AUTOSAR XML (schema 4.0)
standard types defined: uint8, uint16
package /System
  system ExampleSystem
    system mapping SystemMapping
      ecu mapping ECU0_Mapping: ecu=ECU0
  ecu instance ECU0: controller=Controller0
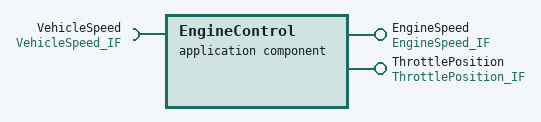
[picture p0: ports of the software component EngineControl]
  application sw component type EngineControl
    provide port EngineSpeed: provided-interface=EngineSpeed_IF
    provide port ThrottlePosition: provided-interface=ThrottlePosition_IF
    require port VehicleSpeed: required-interface=VehicleSpeed_IF
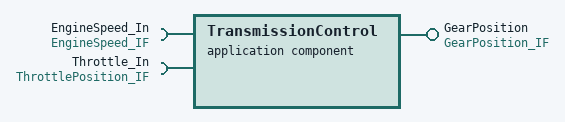
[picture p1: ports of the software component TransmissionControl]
  application sw component type TransmissionControl
    provide port GearPosition: provided-interface=GearPosition_IF
    require port EngineSpeed_In: required-interface=EngineSpeed_IF
    require port Throttle_In: required-interface=ThrottlePosition_IF
  4 x sender receiver interface:
    EngineSpeed_IF
      data EngineSpeed: type=uint16
    ThrottlePosition_IF
      data ThrottlePosition: type=uint8
    VehicleSpeed_IF
      data VehicleSpeed: type=uint16
    GearPosition_IF
      data GearPosition: type=uint8
  module config Can: implementation-config-variant=VARIANT-LINK-TIME, module-description=Can
    CanGeneral: CanDevErrorDetect=true, CanIndex=0, CanMainFunctionPeriod=10.0
